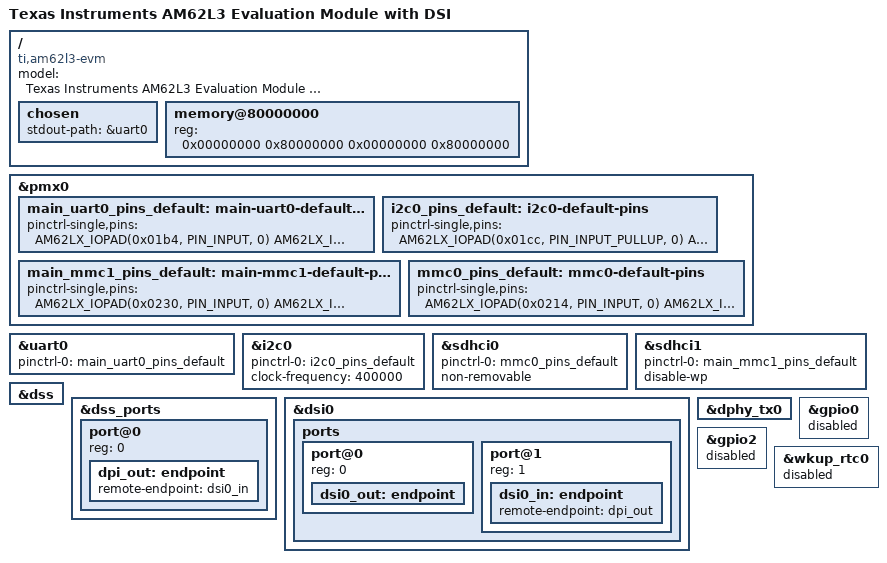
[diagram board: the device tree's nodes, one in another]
// SPDX-License-Identifier: GPL-2.0-only or MIT
/*
 * Device Tree file for the AM62L3 Evaluation Module with DSI Display
 * Copyright (C) 2025 Texas Instruments Incorporated - https://www.ti.com/
 *
 * Minimal device tree configured for DSI display support with the RPi 7-inch
 * touchscreen panel. The k3-am62l3-evm-dsi-rpi-7inch-panel.dtso overlay
 * must be applied to complete the display configuration.
 *
 * Technical Reference Manual: https://www.ti.com/lit/pdf/sprujb4
 * Data Sheet: https://www.ti.com/lit/pdf/sprspa1
 */

/dts-v1/;

#include <dt-bindings/gpio/gpio.h>
#include <dt-bindings/interrupt-controller/irq.h>
#include "k3-am62l3.dtsi"
#include "k3-pinctrl.h"

/ {
	compatible = "ti,am62l3-evm", "ti,am62l3";
	model = "Texas Instruments AM62L3 Evaluation Module with DSI";

	chosen {
		stdout-path = &uart0;
	};

	memory@80000000 {
		reg = <0x00000000 0x80000000 0x00000000 0x80000000>;
		device_type = "memory";
		bootph-all;
	};
};

/* Pinctrl configuration for basic peripherals */
&pmx0 {
	main_uart0_pins_default: main-uart0-default-pins {
		pinctrl-single,pins = <
			AM62LX_IOPAD(0x01b4, PIN_INPUT, 0)	/* (D13) UART0_RXD */
			AM62LX_IOPAD(0x01b8, PIN_OUTPUT, 0)	/* (C13) UART0_TXD */
		>;
		bootph-all;
	};

	i2c0_pins_default: i2c0-default-pins {
		pinctrl-single,pins = <
			AM62LX_IOPAD(0x01cc, PIN_INPUT_PULLUP, 0) /* (B7) I2C0_SCL */
			AM62LX_IOPAD(0x01d0, PIN_INPUT_PULLUP, 0) /* (A7) I2C0_SDA */
		>;
	};

	main_mmc1_pins_default: main-mmc1-default-pins {
		pinctrl-single,pins = <
			AM62LX_IOPAD(0x0230, PIN_INPUT, 0) /* (Y3) MMC1_CMD */
			AM62LX_IOPAD(0x0228, PIN_OUTPUT, 0) /* (Y2) MMC1_CLK */
			AM62LX_IOPAD(0x0224, PIN_INPUT, 0) /* (AA1) MMC1_DAT0 */
			AM62LX_IOPAD(0x0220, PIN_INPUT, 0) /* (Y4) MMC1_DAT1 */
			AM62LX_IOPAD(0x021c, PIN_INPUT, 0) /* (AA2) MMC1_DAT2 */
			AM62LX_IOPAD(0x0218, PIN_INPUT, 0) /* (AB2) MMC1_DAT3 */
			AM62LX_IOPAD(0x0234, PIN_INPUT, 0) /* (B6) MMC1_SDCD */
		>;
		bootph-all;
	};

        mmc0_pins_default: mmc0-default-pins {
                pinctrl-single,pins = <
                        AM62LX_IOPAD(0x0214, PIN_INPUT, 0) /* (D2) MMC0_CMD */
                        AM62LX_IOPAD(0x020c, PIN_OUTPUT, 0) /* (B2) MMC0_CLK */
                        AM62LX_IOPAD(0x0208, PIN_INPUT, 0) /* (D3) MMC0_DAT0 */
                        AM62LX_IOPAD(0x0204, PIN_INPUT_PULLUP, 0) /* (D4) MMC0_DAT1 */
                        AM62LX_IOPAD(0x0200, PIN_INPUT_PULLUP, 0) /* (C1) MMC0_DAT2 */
                        AM62LX_IOPAD(0x01fc, PIN_INPUT_PULLUP, 0) /* (C2) MMC0_DAT3 */
                        AM62LX_IOPAD(0x01f8, PIN_INPUT_PULLUP, 0) /* (C4) MMC0_DAT4 */
                        AM62LX_IOPAD(0x01f4, PIN_INPUT_PULLUP, 0) /* (B3) MMC0_DAT5 */
                        AM62LX_IOPAD(0x01f0, PIN_INPUT_PULLUP, 0) /* (A3) MMC0_DAT6 */
                        AM62LX_IOPAD(0x01ec, PIN_INPUT_PULLUP, 0) /* (B4) MMC0_DAT7 */
                >;
                bootph-all;
        };
};

/* UART0 */
&uart0 {
	pinctrl-names = "default";
	pinctrl-0 = <&main_uart0_pins_default>;
	bootph-all;
	status = "okay";
};

/* I2C0 - Required for DSI display regulator and touch controller */
&i2c0 {
	pinctrl-names = "default";
	pinctrl-0 = <&i2c0_pins_default>;
	clock-frequency = <400000>;
	status = "okay";
};

&sdhci0 {
        /* eMMC */
        pinctrl-names = "default";
        pinctrl-0 = <&mmc0_pins_default>;
        non-removable;
        status = "okay";
        bootph-all;
};

/* SD/MMC */
&sdhci1 {
	pinctrl-names = "default";
	pinctrl-0 = <&main_mmc1_pins_default>;
	disable-wp;
	bootph-all;
	status = "okay";
};

/* Display subsystem - DPI output to DSI bridge */
&dss {
	status = "okay";
	bootph-all;
};

&dss_ports {
	#address-cells = <1>;
	#size-cells = <0>;

	/* VP1: DPI Output to DSI Bridge */
	port@0 {
		reg = <0>;

		dpi_out: endpoint {
			remote-endpoint = <&dsi0_in>;
		};
	};
};

/* DSI Controller - DPI to DSI bridge connection */
&dsi0 {
	status = "okay";
	#address-cells = <1>;
	#size-cells = <0>;

	ports {
		#address-cells = <1>;
		#size-cells = <0>;

		/* DSI output port (to bridge/panel) */
		port@0 {
			reg = <0>;
			dsi0_out: endpoint {
				/* Will be connected by overlay */
			};
		};

		/* DSI input port (from DPI) */
		port@1 {
			reg = <1>;
			dsi0_in: endpoint {
				remote-endpoint = <&dpi_out>;
			};
		};
	};
};

/* DSI Physical Layer */
&dphy_tx0 {
	status = "okay";
};

&gpio0 {
	status = "disabled";
};

&gpio2 {
	status = "disabled";
};

&wkup_rtc0 {
	status = "disabled";
};
